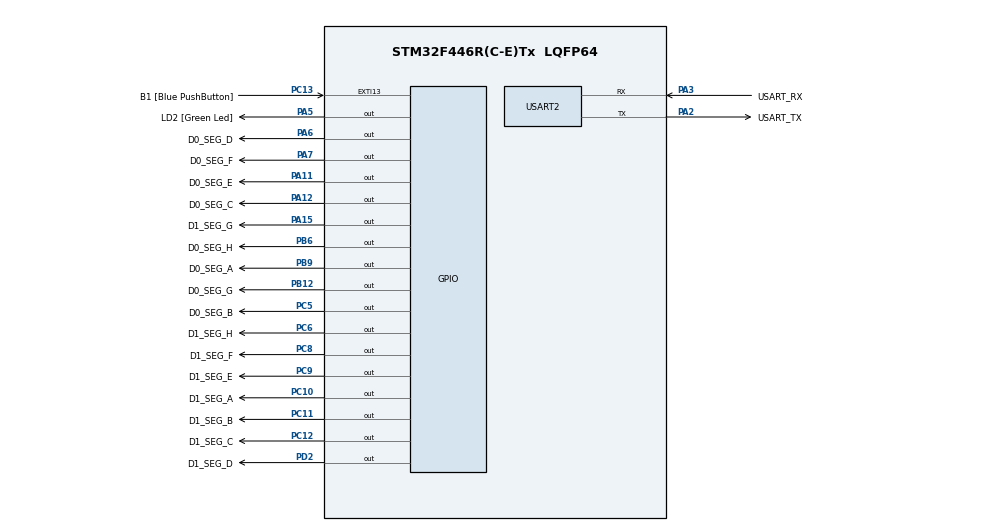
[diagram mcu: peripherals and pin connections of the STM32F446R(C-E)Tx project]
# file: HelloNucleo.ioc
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Mcu.Family=STM32F4
PH0-OSC_IN.Signal=RCC_OSC_IN
RCC.CortexFreq_Value=84000000
PC10.Signal=GPIO_Output
PC12.Signal=GPIO_Output
PA14.GPIO_Label=TCK
PC6.GPIO_Label=D1_SEG_H
PA6.GPIO_Label=D0_SEG_D
PB6.GPIO_Label=D0_SEG_H
PC13.GPIO_Label=B1 [Blue PushButton]
PA5.PinState=GPIO_PIN_RESET
RCC.SYSCLKSource=RCC_SYSCLKSOURCE_PLLCLK
ProjectManager.StackSize=0x400
PC8.PinState=GPIO_PIN_SET
PA15.GPIO_Label=D1_SEG_G
PA12.Signal=GPIO_Output
PA7.PinState=GPIO_PIN_SET
RCC.HCLKFreq_Value=84000000
RCC.APB2TimFreq_Value=84000000
PB6.Signal=GPIO_Output
PB12.PinState=GPIO_PIN_SET
RCC.AHBFreq_Value=84000000
PH0-OSC_IN.Mode=HSE-External-Oscillator
PA12.PinState=GPIO_PIN_SET
RCC.HSE_VALUE=8000000
PB12.GPIO_Label=D0_SEG_G
PC14-OSC32_IN.Mode=LSE-External-Oscillator
PA14.Mode=Serial_Wire
PC11.GPIO_Label=D1_SEG_B
PC10.PinState=GPIO_PIN_SET
RCC.FLatency-AdvancedSettings=FLASH_LATENCY_2
PH1-OSC_OUT.Mode=HSE-External-Oscillator
Mcu.Package=LQFP64
PB9.Signal=GPIO_Output
PA6.Signal=GPIO_Output
USART2.VirtualMode=VM_ASYNC
PA2.GPIO_Label=USART_TX
PA15.Signal=GPIO_Output
RCC.APB1TimFreq_Value=84000000
PC5.Signal=GPIO_Output
PA12.GPIO_Speed=GPIO_SPEED_FREQ_LOW
PA3.Signal=USART2_RX
PB3.GPIO_Label=SWO
PC15-OSC32_OUT.Mode=LSE-External-Oscillator
PB9.GPIO_Label=D0_SEG_A
PC10.GPIO_Label=D1_SEG_A
PC9.GPIO_Label=D1_SEG_E
PC11.Signal=GPIO_Output
PC13.Signal=GPXTI13
PC8.Signal=GPIO_Output
PC6.Signal=GPIO_Output
PC9.PinState=GPIO_PIN_SET
PA11.GPIO_Label=D0_SEG_E
PA6.PinState=GPIO_PIN_SET
RCC.APB1CLKDivider=RCC_HCLK_DIV2
PC14-OSC32_IN.Signal=RCC_OSC32_IN
PA12.GPIO_Label=D0_SEG_C
PC8.GPIO_Label=D1_SEG_F
PA3.Mode=Asynchronous
PA13.Signal=SYS_JTMS-SWDIO
PC12.PinState=GPIO_PIN_SET
ProjectManager.TargetToolchain=STM32CubeIDE
RCC.USBFreq_Value=168000000
PC15-OSC32_OUT.Signal=RCC_OSC32_OUT
PC6.PinState=GPIO_PIN_SET
PA5.Signal=GPIO_Output
PD2.PinState=GPIO_PIN_SET
board=NUCLEO-F446RE
RCC.VCOOutputFreq_Value=336000000
PA15.PinState=GPIO_PIN_SET
RCC.APB2Freq_Value=84000000
PC11.PinState=GPIO_PIN_SET
PH1-OSC_OUT.Signal=RCC_OSC_OUT
PA13.Mode=Serial_Wire
Mcu.Name=STM32F446R(C-E)Tx
PA2.Signal=USART2_TX
PA13.GPIO_Label=TMS
RCC.48MHZClocksFreq_Value=84000000
PB3.Signal=SYS_JTDO-SWO
RCC.SYSCLKFreq_VALUE=84000000
PA7.GPIO_Label=D0_SEG_F
PC5.PinState=GPIO_PIN_SET
PA5.GPIO_Label=LD2 [Green Led]
PC13.GPIO_ModeDefaultEXTI=GPIO_MODE_IT_FALLING
PC5.GPIO_Label=D0_SEG_B
PC12.GPIO_Label=D1_SEG_C
PB6.PinState=GPIO_PIN_SET
PB9.PinState=GPIO_PIN_SET
PA11.Signal=GPIO_Output
PA14.Signal=SYS_JTCK-SWCLK
ProjectManager.HeapSize=0x200
RCC.HSI_VALUE=16000000
RCC.PLLP=RCC_PLLP_DIV4
NVIC.PriorityGroup=NVIC_PRIORITYGROUP_0
RCC.PLLN=336
PA2.Mode=Asynchronous
PC9.Signal=GPIO_Output
PD2.Signal=GPIO_Output
PA11.PinState=GPIO_PIN_SET
RCC.APB1Freq_Value=42000000
PB12.Signal=GPIO_Output
PD2.GPIO_Label=D1_SEG_D
PA3.GPIO_Label=USART_RX
PA7.Signal=GPIO_Output

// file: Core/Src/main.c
/* USER CODE BEGIN Header */
/**
 ******************************************************************************
 * @file           : main.c
 * @brief          : Main program body
 ******************************************************************************
 * @attention
 *
 * <h2><center>&copy; Copyright (c) 2021 STMicroelectronics.
 * All rights reserved.</center></h2>
 *
 * This software component is licensed by ST under BSD 3-Clause license,
 * the "License"; You may not use this file except in compliance with the
 * License. You may obtain a copy of the License at:
 *                        opensource.org/licenses/BSD-3-Clause
 *
 ******************************************************************************
 */
/* USER CODE END Header */
#include "main.h"

/* USER CODE BEGIN Includes */

#include "Display.h"

/* USER CODE END Includes */

UART_HandleTypeDef huart2;

void SystemClock_Config (void);
static void MX_GPIO_Init (void);
static void MX_USART2_UART_Init (void);

int main (void)
{

    /* MCU Configuration--------------------------------------------------------*/

    /* Reset of all peripherals, Initializes the Flash interface and the Systick. */
    HAL_Init ();

    /* Configure the system clock */
    SystemClock_Config ();

    /* Initialize all configured peripherals */
    MX_GPIO_Init ();
    MX_USART2_UART_Init ();
    /* USER CODE BEGIN 2 */

//    GPIO_TypeDef *d0Ports[] =
//        { D0_SEG_A_GPIO_Port, D0_SEG_B_GPIO_Port, D0_SEG_C_GPIO_Port,
//        D0_SEG_D_GPIO_Port, D0_SEG_E_GPIO_Port, D0_SEG_F_GPIO_Port,
//        D0_SEG_G_GPIO_Port, D0_SEG_H_GPIO_Port };
//
//    uint16_t d0Pins[] =
//        { D0_SEG_A_Pin, D0_SEG_B_Pin, D0_SEG_C_Pin, D0_SEG_D_Pin,
//        D0_SEG_E_Pin, D0_SEG_F_Pin, D0_SEG_G_Pin, D0_SEG_H_Pin };
//
//    GPIO_TypeDef *d1Ports[] =
//        { D1_SEG_A_GPIO_Port, D1_SEG_B_GPIO_Port, D1_SEG_C_GPIO_Port,
//        D1_SEG_D_GPIO_Port, D1_SEG_E_GPIO_Port, D1_SEG_F_GPIO_Port,
//        D1_SEG_G_GPIO_Port, D1_SEG_H_GPIO_Port };
//
//    uint16_t d1Pins[] =
//        { D1_SEG_A_Pin, D1_SEG_B_Pin, D1_SEG_C_Pin, D1_SEG_D_Pin,
//        D1_SEG_E_Pin, D1_SEG_F_Pin, D1_SEG_G_Pin, D1_SEG_H_Pin };

    /* USER CODE END 2 */

    /* Infinite loop */
    while (1)
    {

    }
}

void SystemClock_Config (void)
{
    RCC_OscInitTypeDef RCC_OscInitStruct =
        { 0 };
    RCC_ClkInitTypeDef RCC_ClkInitStruct =
        { 0 };

    /** Configure the main internal regulator output voltage
     */
    __HAL_RCC_PWR_CLK_ENABLE();
    __HAL_PWR_VOLTAGESCALING_CONFIG(PWR_REGULATOR_VOLTAGE_SCALE3);
    /** Initializes the RCC Oscillators according to the specified parameters
     * in the RCC_OscInitTypeDef structure.
     */
    RCC_OscInitStruct.OscillatorType = RCC_OSCILLATORTYPE_HSI;
    RCC_OscInitStruct.HSIState = RCC_HSI_ON;
    RCC_OscInitStruct.HSICalibrationValue = RCC_HSICALIBRATION_DEFAULT;
    RCC_OscInitStruct.PLL.PLLState = RCC_PLL_ON;
    RCC_OscInitStruct.PLL.PLLSource = RCC_PLLSOURCE_HSI;
    RCC_OscInitStruct.PLL.PLLM = 16;
    RCC_OscInitStruct.PLL.PLLN = 336;
    RCC_OscInitStruct.PLL.PLLP = RCC_PLLP_DIV4;
    RCC_OscInitStruct.PLL.PLLQ = 2;
    RCC_OscInitStruct.PLL.PLLR = 2;
    if (HAL_RCC_OscConfig (&RCC_OscInitStruct) != HAL_OK)
    {
        Error_Handler ();
    }
    /** Initializes the CPU, AHB and APB buses clocks
     */
    RCC_ClkInitStruct.ClockType = RCC_CLOCKTYPE_HCLK | RCC_CLOCKTYPE_SYSCLK
            | RCC_CLOCKTYPE_PCLK1 | RCC_CLOCKTYPE_PCLK2;
    RCC_ClkInitStruct.SYSCLKSource = RCC_SYSCLKSOURCE_PLLCLK;
    RCC_ClkInitStruct.AHBCLKDivider = RCC_SYSCLK_DIV1;
    RCC_ClkInitStruct.APB1CLKDivider = RCC_HCLK_DIV2;
    RCC_ClkInitStruct.APB2CLKDivider = RCC_HCLK_DIV1;

    if (HAL_RCC_ClockConfig (&RCC_ClkInitStruct, FLASH_LATENCY_2) != HAL_OK)
    {
        Error_Handler ();
    }
}

static void MX_USART2_UART_Init (void)
{

    huart2.Instance = USART2;
    huart2.Init.BaudRate = 115200;
    huart2.Init.WordLength = UART_WORDLENGTH_8B;
    huart2.Init.StopBits = UART_STOPBITS_1;
    huart2.Init.Parity = UART_PARITY_NONE;
    huart2.Init.Mode = UART_MODE_TX_RX;
    huart2.Init.HwFlowCtl = UART_HWCONTROL_NONE;
    huart2.Init.OverSampling = UART_OVERSAMPLING_16;
    if (HAL_UART_Init (&huart2) != HAL_OK)
    {
        Error_Handler ();
    }

}

static void MX_GPIO_Init (void)
{
    GPIO_InitTypeDef GPIO_InitStruct =
        { 0 };

    /* GPIO Ports Clock Enable */
    __HAL_RCC_GPIOC_CLK_ENABLE();
    __HAL_RCC_GPIOH_CLK_ENABLE();
    __HAL_RCC_GPIOA_CLK_ENABLE();
    __HAL_RCC_GPIOB_CLK_ENABLE();
    __HAL_RCC_GPIOD_CLK_ENABLE();

    /*Configure GPIO pin Output Level */
    HAL_GPIO_WritePin (LD2_GPIO_Port, LD2_Pin, GPIO_PIN_RESET);

    /*Configure GPIO pin Output Level */
    HAL_GPIO_WritePin (
            GPIOA,
            D0_SEG_D_Pin | D0_SEG_F_Pin | D0_SEG_E_Pin | D0_SEG_C_Pin
                    | D1_SEG_G_Pin,
            GPIO_PIN_SET);

    /*Configure GPIO pin Output Level */
    HAL_GPIO_WritePin (
            GPIOC,
            D0_SEG_B_Pin | D1_SEG_H_Pin | D1_SEG_F_Pin | D1_SEG_E_Pin
                    | D1_SEG_A_Pin | D1_SEG_B_Pin | D1_SEG_C_Pin,
            GPIO_PIN_SET);

    /*Configure GPIO pin Output Level */
    HAL_GPIO_WritePin (GPIOB, D0_SEG_G_Pin | D0_SEG_H_Pin | D0_SEG_A_Pin,
                       GPIO_PIN_SET);

    /*Configure GPIO pin Output Level */
    HAL_GPIO_WritePin (D1_SEG_D_GPIO_Port, D1_SEG_D_Pin, GPIO_PIN_SET);

    /*Configure GPIO pin : B1_Pin */
    GPIO_InitStruct.Pin = B1_Pin;
    GPIO_InitStruct.Mode = GPIO_MODE_IT_FALLING;
    GPIO_InitStruct.Pull = GPIO_NOPULL;
    HAL_GPIO_Init (B1_GPIO_Port, &GPIO_InitStruct);

    /*Configure GPIO pins : LD2_Pin D0_SEG_D_Pin D0_SEG_F_Pin D0_SEG_E_Pin
     D0_SEG_C_Pin D1_SEG_G_Pin */
    GPIO_InitStruct.Pin = LD2_Pin | D0_SEG_D_Pin | D0_SEG_F_Pin | D0_SEG_E_Pin
            | D0_SEG_C_Pin | D1_SEG_G_Pin;
    GPIO_InitStruct.Mode = GPIO_MODE_OUTPUT_PP;
    GPIO_InitStruct.Pull = GPIO_NOPULL;
    GPIO_InitStruct.Speed = GPIO_SPEED_FREQ_LOW;
    HAL_GPIO_Init (GPIOA, &GPIO_InitStruct);

    /*Configure GPIO pins : D0_SEG_B_Pin D1_SEG_H_Pin D1_SEG_F_Pin D1_SEG_E_Pin
     D1_SEG_A_Pin D1_SEG_B_Pin D1_SEG_C_Pin */
    GPIO_InitStruct.Pin = D0_SEG_B_Pin | D1_SEG_H_Pin | D1_SEG_F_Pin
            | D1_SEG_E_Pin | D1_SEG_A_Pin | D1_SEG_B_Pin | D1_SEG_C_Pin;
    GPIO_InitStruct.Mode = GPIO_MODE_OUTPUT_PP;
    GPIO_InitStruct.Pull = GPIO_NOPULL;
    GPIO_InitStruct.Speed = GPIO_SPEED_FREQ_LOW;
    HAL_GPIO_Init (GPIOC, &GPIO_InitStruct);

    /*Configure GPIO pins : D0_SEG_G_Pin D0_SEG_H_Pin D0_SEG_A_Pin */
    GPIO_InitStruct.Pin = D0_SEG_G_Pin | D0_SEG_H_Pin | D0_SEG_A_Pin;
    GPIO_InitStruct.Mode = GPIO_MODE_OUTPUT_PP;
    GPIO_InitStruct.Pull = GPIO_NOPULL;
    GPIO_InitStruct.Speed = GPIO_SPEED_FREQ_LOW;
    HAL_GPIO_Init (GPIOB, &GPIO_InitStruct);

    /*Configure GPIO pin : D1_SEG_D_Pin */
    GPIO_InitStruct.Pin = D1_SEG_D_Pin;
    GPIO_InitStruct.Mode = GPIO_MODE_OUTPUT_PP;
    GPIO_InitStruct.Pull = GPIO_NOPULL;
    GPIO_InitStruct.Speed = GPIO_SPEED_FREQ_LOW;
    HAL_GPIO_Init (D1_SEG_D_GPIO_Port, &GPIO_InitStruct);

}

void Error_Handler (void)
{
    /* USER CODE BEGIN Error_Handler_Debug */
    /* User can add his own implementation to report the HAL error return state */
    __disable_irq ();
    while (1)
    {
    }
    /* USER CODE END Error_Handler_Debug */
}

/************************ (C) COPYRIGHT STMicroelectronics *****END OF FILE****/
